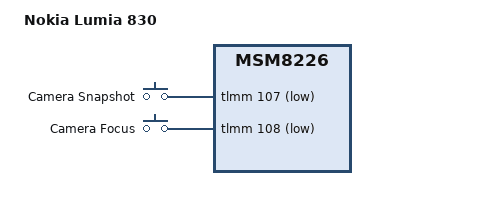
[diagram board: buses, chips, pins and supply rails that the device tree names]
// SPDX-License-Identifier: BSD-3-Clause
/*
 * Copyright (c) 2022, Jack Matthews <jm5112356@gmail.com>
 * Copyright (c) 2022, Ivaylo Ivanov <ivo.ivanov.ivanov1@gmail.com>
 * Copyright (c) 2022, Dominik Kobinski <dominikkobinski314@gmail.com>
 * Copyright (c) 2022, Rayyan Ansari <rayyan@ansari.sh>
 */

/dts-v1/;

#include "qcom-msm8226-microsoft-common.dtsi"

/ {
	model = "Nokia Lumia 830";
	compatible = "microsoft,tesla", "qcom,msm8226";
	chassis-type = "handset";
};

&gpio_keys {
	camera-snapshot {
		label = "Camera Snapshot";
		gpios = <&tlmm 107 GPIO_ACTIVE_LOW>;
		linux,code = <KEY_CAMERA>;
	};

	camera-focus {
		label = "Camera Focus";
		gpios = <&tlmm 108 GPIO_ACTIVE_LOW>;
		linux,code = <KEY_CAMERA_FOCUS>;
	};
};
